# N32L403 register map
Vendor: Nationstech Ltd.; File version: 1.0
Registers are 32-bit, read-write, reset 0x0 unless marked. A register's access mark holds for its fields unless they carry their own. Offsets are from the block's base; [hi:lo] are bit positions; {n}, {i} and the like mark numbered series.

## EXTI — external interrupt/event controller
Base 0x40010400
0x00 EXTI_IMASK
  [27:0] IMASK
0x04 EXTI_EMASK
  [27:0] EMASK
0x08 EXTI_RT_CFG
  [27:0] RT_CFG
0x0C EXTI_FT_CFG
  [27:0] FT_CFG
0x10 EXTI_SWIE
  [27:0] SWIE
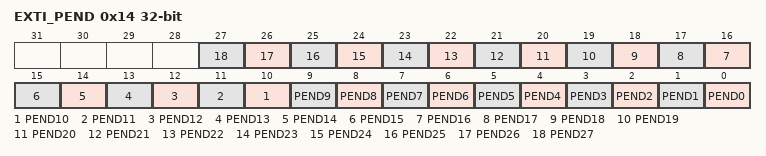
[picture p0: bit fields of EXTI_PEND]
0x14 EXTI_PEND
  [n] PEND{n} (n=0..27)
0x18 EXTI_TS_SEL
  [3:0] TSSEL

## FLASH — interal FLASH controller
Base 0x40022000
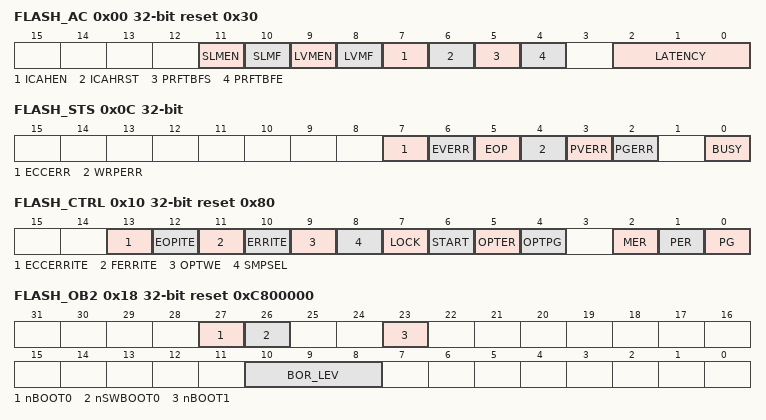
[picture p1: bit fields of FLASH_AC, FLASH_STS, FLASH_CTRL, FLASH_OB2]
0x00 FLASH_AC reset 0x30
  [11] SLMEN, [10] SLMF, [9] LVMEN, [8] LVMF, [7] ICAHEN, [6] ICAHRST, [5] PRFTBFS, [4] PRFTBFE, [2:0] LATENCY
0x04 FLASH_KEY
  [31:0] FKEY
0x08 FLASH_OPTKEY
0x0C FLASH_STS
  [7] ECCERR, [6] EVERR, [5] EOP, [4] WRPERR, [3] PVERR, [2] PGERR, [0] BUSY
0x10 FLASH_CTRL reset 0x80
  [13] ECCERRITE, [12] EOPITE, [11] FERRITE, [10] ERRITE, [9] OPTWE, [8] SMPSEL, [7] LOCK, [6] START, [5] OPTER, [4] OPTPG, [2] MER, [1] PER, [0] PG
0x14 FLASH_ADD
  [31:0] FADD
0x18 FLASH_OB2 reset 0xC800000
  [27] nBOOT0, [26] nSWBOOT0, [23] nBOOT1, [10:8] BOR_LEV
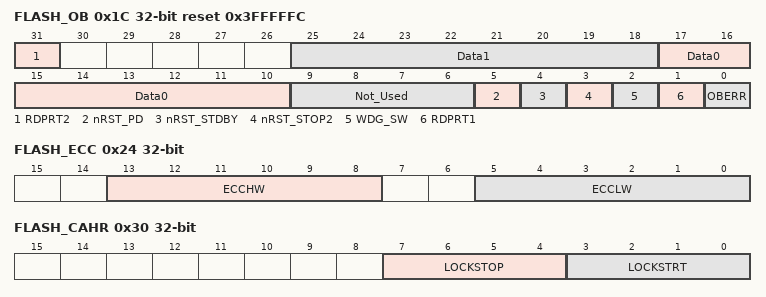
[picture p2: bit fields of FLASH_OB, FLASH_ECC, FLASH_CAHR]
0x1C FLASH_OB reset 0x3FFFFFC
  [31] RDPRT2, [25:18] Data1, [17:10] Data0, [9:6] Not_Used, [5] nRST_PD, [4] nRST_STDBY, [3] nRST_STOP2, [2] WDG_SW, [1] RDPRT1, [0] OBERR
0x20 FLASH_WRP reset 0xFFFFFFFF
  [31:0] WRPT
0x24 FLASH_ECC
  [13:8] ECCHW, [5:0] ECCLW
0x30 FLASH_CAHR
  [7:4] LOCKSTOP, [3:0] LOCKSTRT

## GPIOA — General purpose I/O
Base 0x40010800
Same registers: GPIOB 0x40010C00, GPIOC 0x40011000, GPIOD 0x40011400
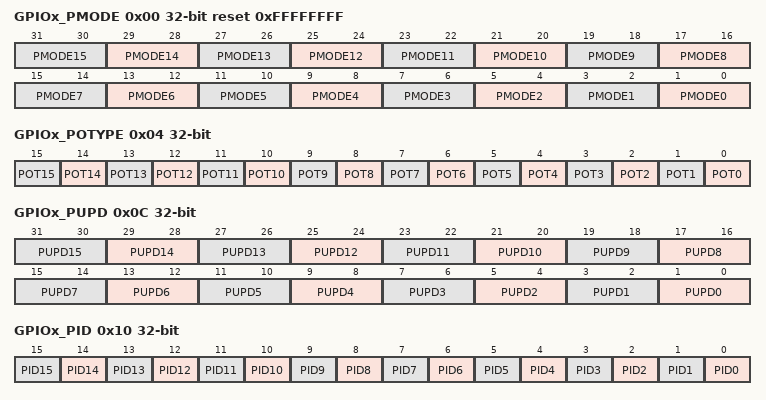
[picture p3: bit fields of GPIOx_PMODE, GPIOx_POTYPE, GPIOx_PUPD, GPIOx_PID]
0x00 GPIOx_PMODE reset 0xFFFFFFFF
  [2n+1:2n] PMODE{n} (n=0..15)
0x04 GPIOx_POTYPE
  [n] POT{n} (n=0..15)
0x0C GPIOx_PUPD
  [2n+1:2n] PUPD{n} (n=0..15)
0x10 GPIOx_PID
  [n] PID{n} (n=0..15)
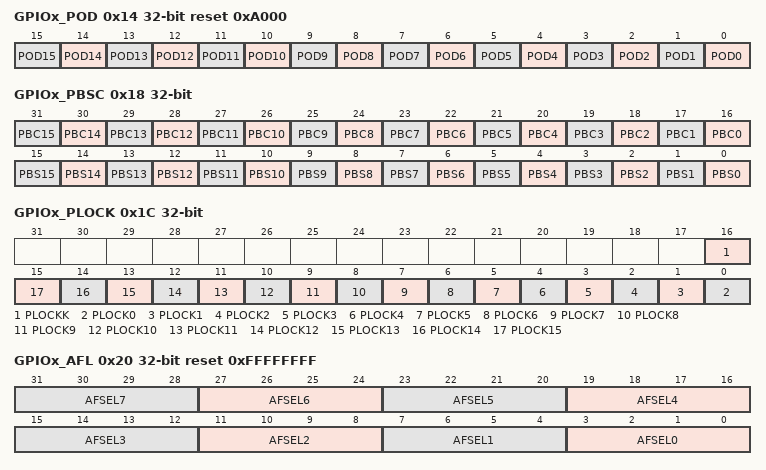
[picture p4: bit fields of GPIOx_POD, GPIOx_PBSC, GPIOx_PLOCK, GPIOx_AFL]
0x14 GPIOx_POD reset 0xA000
  [n] POD{n} (n=0..15)
0x18 GPIOx_PBSC
  [n+16] PBC{n} (n=0..15), [n] PBS{n} (n=0..15)
0x1C GPIOx_PLOCK
  [16] PLOCKK, [n] PLOCK{n} (n=0..15)
0x20 GPIOx_AFL reset 0xFFFFFFFF
  [4n+3:4n] AFSEL{n} (n=0..7)
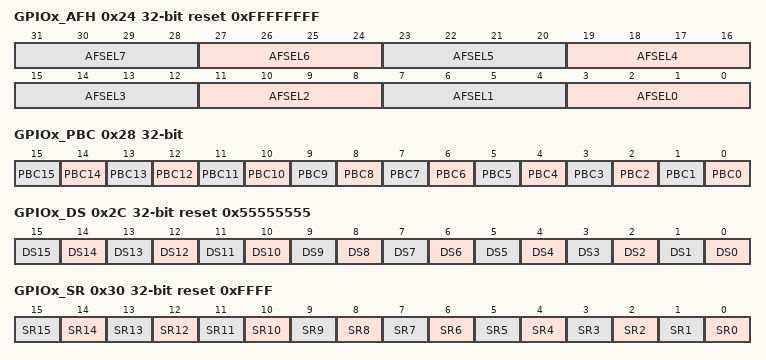
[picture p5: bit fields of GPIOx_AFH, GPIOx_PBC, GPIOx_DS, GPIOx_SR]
0x24 GPIOx_AFH reset 0xFFFFFFFF
  [4n+3:4n] AFSEL{n} (n=0..7)
0x28 GPIOx_PBC
  [n] PBC{n} (n=0..15)
0x2C GPIOx_DS reset 0x55555555
  [n] DS{n} (n=0..15)
0x30 GPIOx_SR reset 0xFFFF
  [n] SR{n} (n=0..15)

## AFIO — Alternate function I/O
Base 0x40010000
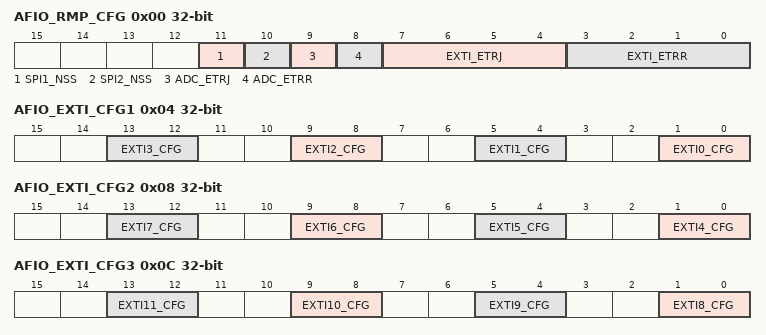
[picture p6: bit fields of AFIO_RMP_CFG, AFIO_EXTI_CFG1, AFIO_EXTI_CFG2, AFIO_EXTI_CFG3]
0x00 AFIO_RMP_CFG
  [11] SPI1_NSS, [10] SPI2_NSS, [9] ADC_ETRJ, [8] ADC_ETRR, [7:4] EXTI_ETRJ, [3:0] EXTI_ETRR
0x04 AFIO_EXTI_CFG1
  [4n+1:4n] EXTI{n}_CFG (n=0..3)
0x08 AFIO_EXTI_CFG2
  [4n-15:4n-16] EXTI{n}_CFG (n=4..7)
0x0C AFIO_EXTI_CFG3
  [4n-31:4n-32] EXTI{n}_CFG (n=8..11)
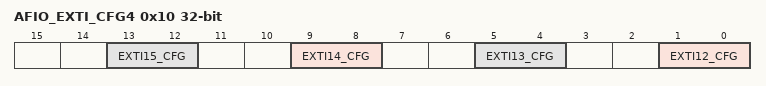
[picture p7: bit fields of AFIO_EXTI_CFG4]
0x10 AFIO_EXTI_CFG4
  [4n-47:4n-48] EXTI{n}_CFG (n=12..15)

## I2C1 — Inter integrated circuit
Base 0x40005400
Same registers: I2C2 0x40005800
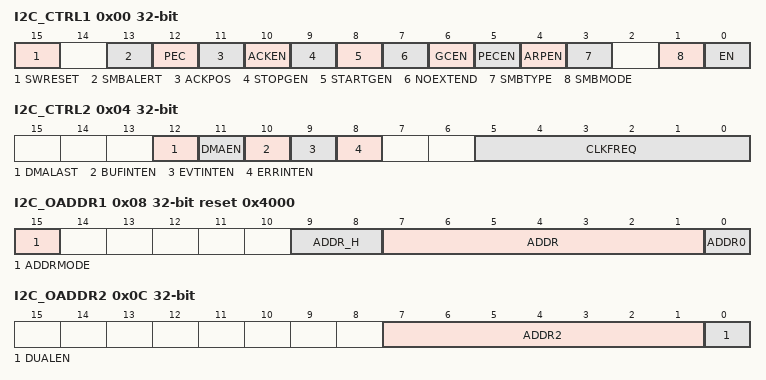
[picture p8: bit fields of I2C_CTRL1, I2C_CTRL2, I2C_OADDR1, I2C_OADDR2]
0x00 I2C_CTRL1
  [15] SWRESET, [13] SMBALERT, [12] PEC, [11] ACKPOS, [10] ACKEN, [9] STOPGEN, [8] STARTGEN, [7] NOEXTEND, [6] GCEN, [5] PECEN, [4] ARPEN, [3] SMBTYPE, [1] SMBMODE, [0] EN
0x04 I2C_CTRL2
  [12] DMALAST, [11] DMAEN, [10] BUFINTEN, [9] EVTINTEN, [8] ERRINTEN, [5:0] CLKFREQ
0x08 I2C_OADDR1 reset 0x4000
  [15] ADDRMODE, [9:8] ADDR_H, [7:1] ADDR, [0] ADDR0
0x0C I2C_OADDR2
  [7:1] ADDR2, [0] DUALEN
0x10 I2C_DAT
  [7:0] DATA
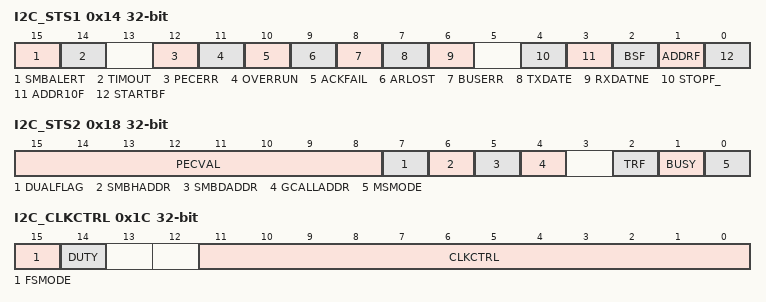
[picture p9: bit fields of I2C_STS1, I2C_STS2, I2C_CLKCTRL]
0x14 I2C_STS1
  [15] SMBALERT, [14] TIMOUT, [12] PECERR, [11] OVERRUN, [10] ACKFAIL, [9] ARLOST, [8] BUSERR, [7] TXDATE, [6] RXDATNE, [4] STOPF_, [3] ADDR10F, [2] BSF, [1] ADDRF, [0] STARTBF
0x18 I2C_STS2
  [15:8] PECVAL, [7] DUALFLAG, [6] SMBHADDR, [5] SMBDADDR, [4] GCALLADDR, [2] TRF, [1] BUSY, [0] MSMODE
0x1C I2C_CLKCTRL
  [15] FSMODE, [14] DUTY, [11:0] CLKCTRL
0x20 I2C_TMRISE
  [5:0] TMRISE

## IWDG — Independent watchdog
Base 0x40003000
0x00 IWDG_KEY
  [15:0] KEYV
0x04 IWDG_PREDIV
  [2:0] PD
0x08 IWDG_RELV reset 0xFFF
  [11:0] REL
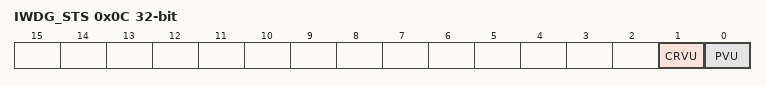
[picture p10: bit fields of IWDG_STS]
0x0C IWDG_STS
  [1] CRVU, [0] PVU

## LPTIM — Low power timer control
Base 0x40004C00
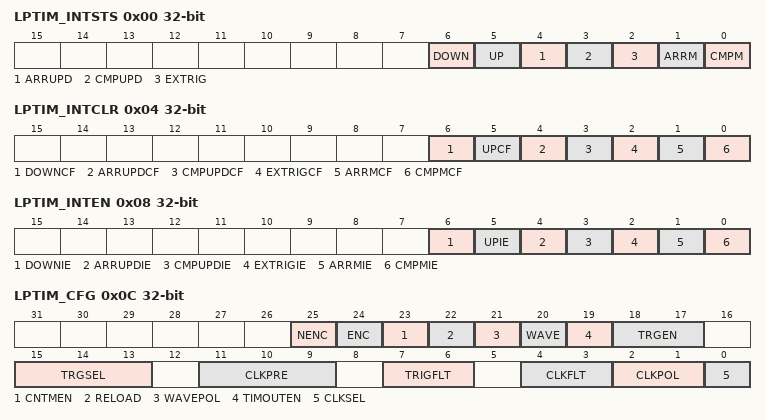
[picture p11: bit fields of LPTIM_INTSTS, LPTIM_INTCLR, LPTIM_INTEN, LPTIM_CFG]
0x00 LPTIM_INTSTS read
  [6] DOWN, [5] UP, [4] ARRUPD, [3] CMPUPD, [2] EXTRIG, [1] ARRM, [0] CMPM
0x04 LPTIM_INTCLR write
  [6] DOWNCF, [5] UPCF, [4] ARRUPDCF, [3] CMPUPDCF, [2] EXTRIGCF, [1] ARRMCF, [0] CMPMCF
0x08 LPTIM_INTEN
  [6] DOWNIE, [5] UPIE, [4] ARRUPDIE, [3] CMPUPDIE, [2] EXTRIGIE, [1] ARRMIE, [0] CMPMIE
0x0C LPTIM_CFG (reset mask 0x3FEEEEF)
  [25] NENC, [24] ENC, [23] CNTMEN, [22] RELOAD, [21] WAVEPOL, [20] WAVE, [19] TIMOUTEN, [18:17] TRGEN, [15:13] TRGSEL, [11:9] CLKPRE, [7:6] TRIGFLT, [4:3] CLKFLT, [2:1] CLKPOL, [0] CLKSEL
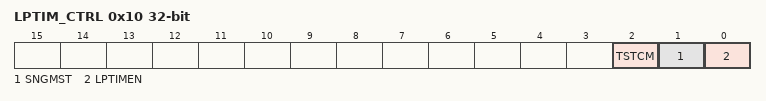
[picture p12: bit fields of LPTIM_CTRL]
0x10 LPTIM_CTRL
  [2] TSTCM, [1] SNGMST, [0] LPTIMEN
0x14 LPTIM_CMP
  [15:0] CMPVAL
0x18 LPTIM_ARR reset 0x1
  [15:0] ARRVAL
0x1C LPTIM_CNT reset 0x1
  [15:0] CNTVAL
